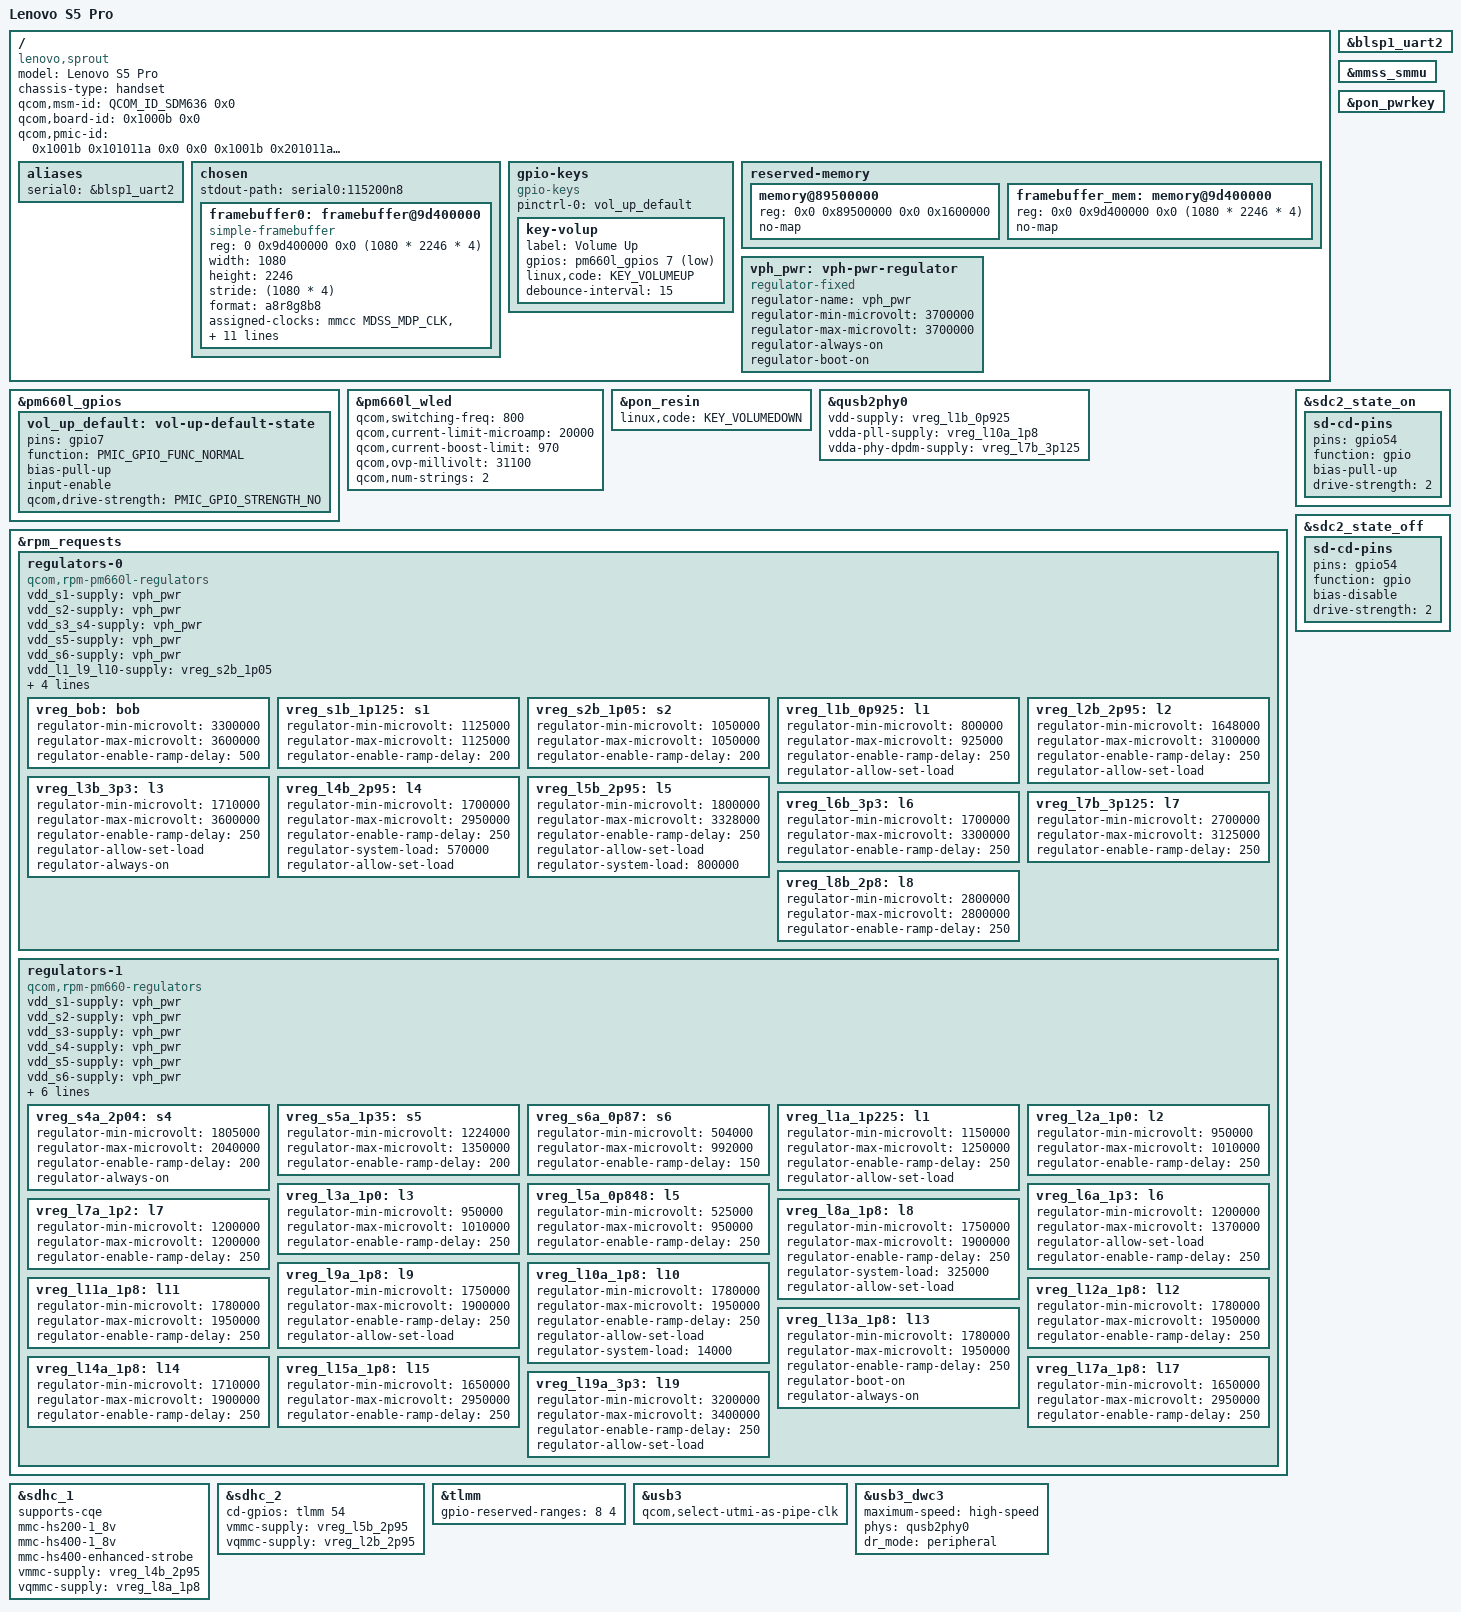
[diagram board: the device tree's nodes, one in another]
// SPDX-License-Identifier: BSD-3-Clause
// SPDX-FileCopyrightText: 2026 Andrey Derkach <gabin278@gmail.com>
/*
 * Lenovo S5 Pro (L58041, "sprout")
 *
 * Based on sdm636-xiaomi-whyred.dts. Board-specific values come from the
 * vendor device tree the stock bootloader selects for this board
 * (msm-id 345, board-id 0x1000b, "SDM 636 PM660 + PM660L QRD").
 */

/dts-v1/;

#include "sdm636.dtsi"
#include "pm660.dtsi"
#include "pm660l.dtsi"
#include <dt-bindings/arm/qcom,ids.h>
#include <dt-bindings/gpio/gpio.h>
#include <dt-bindings/input/input.h>
#include <dt-bindings/input/gpio-keys.h>
#include <dt-bindings/pinctrl/qcom,pmic-gpio.h>

/ {
	model = "Lenovo S5 Pro";
	compatible = "lenovo,sprout", "qcom,sdm636";
	chassis-type = "handset";

	/* Matches the board the stock ABL reports, so it picks this DTB */
	qcom,msm-id = <QCOM_ID_SDM636 0x0>;
	qcom,board-id = <0x1000b 0x0>;
	qcom,pmic-id = <0x1001b 0x101011a 0x0 0x0 0x1001b 0x201011a 0x0 0x0>;

	aliases {
		serial0 = &blsp1_uart2; /* Debug UART */
	};

	chosen {
		#address-cells = <2>;
		#size-cells = <2>;
		ranges;

		stdout-path = "serial0:115200n8";

		framebuffer0: framebuffer@9d400000 {
			compatible = "simple-framebuffer";
			reg = <0 0x9d400000 0x0 (1080 * 2246 * 4)>;
			width = <1080>;
			height = <2246>;
			stride = <(1080 * 4)>;
			format = "a8r8g8b8";

			/*
			 * Keep the bootloader-enabled display stack alive so that
			 * simplefb keeps working without clk_ignore_unused and
			 * pd_ignore_unused.
			 */
			assigned-clocks = <&mmcc MDSS_MDP_CLK>,
					  <&mmcc MDSS_VSYNC_CLK>;
			assigned-clock-rates = <300000000>,
					       <19200000>;
			clocks = <&mmcc MDSS_AHB_CLK>,
				 <&mmcc MDSS_AXI_CLK>,
				 <&mmcc MDSS_VSYNC_CLK>,
				 <&mmcc MDSS_MDP_CLK>,
				 <&mmcc BYTE0_CLK_SRC>,
				 <&mmcc PCLK0_CLK_SRC>,
				 <&mmcc MDSS_BYTE0_CLK>,
				 <&mmcc MDSS_BYTE0_INTF_CLK>,
				 <&mmcc MNOC_AHB_CLK>,
				 <&mmcc MISC_AHB_CLK>,
				 <&mmcc MDSS_PCLK0_CLK>,
				 <&mmcc MDSS_ESC0_CLK>;

			power-domains = <&rpmpd SDM660_VDDCX>, <&mmcc MDSS_GDSC>;
		};
	};

	gpio-keys {
		compatible = "gpio-keys";

		pinctrl-0 = <&vol_up_default>;
		pinctrl-names = "default";

		key-volup {
			label = "Volume Up";
			gpios = <&pm660l_gpios 7 GPIO_ACTIVE_LOW>;
			linux,code = <KEY_VOLUMEUP>;
			debounce-interval = <15>;
		};
	};

	reserved-memory {
		#address-cells = <2>;
		#size-cells = <2>;
		ranges;

		/*
		 * The stock firmware reserves 0x85800000-0x8aafffff
		 * ("removed_regions"), sdm630.dtsi only up to 0x89500000.
		 * SD card DMA into the rest stalls the SDHCI controller and
		 * locks up the system.
		 */
		memory@89500000 {
			reg = <0x0 0x89500000 0x0 0x1600000>;
			no-map;
		};

		framebuffer_mem: memory@9d400000 {
			reg = <0x0 0x9d400000 0x0 (1080 * 2246 * 4)>;
			no-map;
		};
	};

	vph_pwr: vph-pwr-regulator {
		compatible = "regulator-fixed";
		regulator-name = "vph_pwr";
		regulator-min-microvolt = <3700000>;
		regulator-max-microvolt = <3700000>;

		regulator-always-on;
		regulator-boot-on;
	};
};

&blsp1_uart2 {
	status = "okay";
};

/*
 * The display fetches the framebuffer through this SMMU; without it, its
 * clocks are turned off as unused and the simple-framebuffer stops updating.
 */
&mmss_smmu {
	status = "okay";
};

&pm660l_gpios {
	vol_up_default: vol-up-default-state {
		pins = "gpio7";
		function = PMIC_GPIO_FUNC_NORMAL;
		bias-pull-up;
		input-enable;
		qcom,drive-strength = <PMIC_GPIO_STRENGTH_NO>;
	};
};

&pm660l_wled {
	qcom,switching-freq = <800>;
	qcom,current-limit-microamp = <20000>;
	qcom,current-boost-limit = <970>;
	qcom,ovp-millivolt = <31100>;
	qcom,num-strings = <2>;

	status = "okay";
};

&pon_pwrkey {
	status = "okay";
};

&pon_resin {
	linux,code = <KEY_VOLUMEDOWN>;

	status = "okay";
};

&qusb2phy0 {
	vdd-supply = <&vreg_l1b_0p925>;
	vdda-pll-supply = <&vreg_l10a_1p8>;
	vdda-phy-dpdm-supply = <&vreg_l7b_3p125>;

	status = "okay";
};

&rpm_requests {
	regulators-0 {
		compatible = "qcom,rpm-pm660l-regulators";

		vdd_s1-supply = <&vph_pwr>;
		vdd_s2-supply = <&vph_pwr>;
		vdd_s3_s4-supply = <&vph_pwr>;
		vdd_s5-supply = <&vph_pwr>;
		vdd_s6-supply = <&vph_pwr>;

		vdd_l1_l9_l10-supply = <&vreg_s2b_1p05>;
		vdd_l2-supply = <&vreg_bob>;
		vdd_l3_l5_l7_l8-supply = <&vreg_bob>;
		vdd_l4_l6-supply = <&vreg_bob>;
		vdd_bob-supply = <&vph_pwr>;

		vreg_bob: bob {
			regulator-min-microvolt = <3300000>;
			regulator-max-microvolt = <3600000>;
			regulator-enable-ramp-delay = <500>;
		};

		vreg_s1b_1p125: s1 {
			regulator-min-microvolt = <1125000>;
			regulator-max-microvolt = <1125000>;
			regulator-enable-ramp-delay = <200>;
		};

		vreg_s2b_1p05: s2 {
			regulator-min-microvolt = <1050000>;
			regulator-max-microvolt = <1050000>;
			regulator-enable-ramp-delay = <200>;
		};

		/* LDOs */
		vreg_l1b_0p925: l1 {
			regulator-min-microvolt = <800000>;
			regulator-max-microvolt = <925000>;
			regulator-enable-ramp-delay = <250>;
			regulator-allow-set-load;
		};

		/* SDHCI 3.3V signal doesn't seem to be supported. */
		vreg_l2b_2p95: l2 {
			regulator-min-microvolt = <1648000>;
			regulator-max-microvolt = <3100000>;
			regulator-enable-ramp-delay = <250>;
			regulator-allow-set-load;
		};

		vreg_l3b_3p3: l3 {
			regulator-min-microvolt = <1710000>;
			regulator-max-microvolt = <3600000>;
			regulator-enable-ramp-delay = <250>;
			regulator-allow-set-load;
			regulator-always-on;
		};

		vreg_l4b_2p95: l4 {
			regulator-min-microvolt = <1700000>;
			regulator-max-microvolt = <2950000>;
			regulator-enable-ramp-delay = <250>;

			regulator-system-load = <570000>;
			regulator-allow-set-load;
		};

		/*
		 * Downstream specifies a range of 1721-3600mV,
		 * but the only assigned consumers are SDHCI2 VMMC
		 * and Coresight QPDI that both request pinned 2.95V.
		 * Tighten the range to 1.8-3.328 (closest to 3.3) to
		 * make the mmc driver happy.
		 */
		vreg_l5b_2p95: l5 {
			regulator-min-microvolt = <1800000>;
			regulator-max-microvolt = <3328000>;
			regulator-enable-ramp-delay = <250>;
			regulator-allow-set-load;
			regulator-system-load = <800000>;
		};

		/* DSI 3.3V and fingerprint sensor */
		vreg_l6b_3p3: l6 {
			regulator-min-microvolt = <1700000>;
			regulator-max-microvolt = <3300000>;
			regulator-enable-ramp-delay = <250>;
		};

		vreg_l7b_3p125: l7 {
			regulator-min-microvolt = <2700000>;
			regulator-max-microvolt = <3125000>;
			regulator-enable-ramp-delay = <250>;
		};

		vreg_l8b_2p8: l8 {
			regulator-min-microvolt = <2800000>;
			regulator-max-microvolt = <2800000>;
			regulator-enable-ramp-delay = <250>;
		};
	};

	regulators-1 {
		compatible = "qcom,rpm-pm660-regulators";

		vdd_s1-supply = <&vph_pwr>;
		vdd_s2-supply = <&vph_pwr>;
		vdd_s3-supply = <&vph_pwr>;
		vdd_s4-supply = <&vph_pwr>;
		vdd_s5-supply = <&vph_pwr>;
		vdd_s6-supply = <&vph_pwr>;

		vdd_l1_l6_l7-supply = <&vreg_s5a_1p35>;
		vdd_l2_l3-supply = <&vreg_s2b_1p05>;
		vdd_l5-supply = <&vreg_s2b_1p05>;
		vdd_l8_l9_l10_l11_l12_l13_l14-supply = <&vreg_s4a_2p04>;
		vdd_l15_l16_l17_l18_l19-supply = <&vreg_bob>;

		/*
		 * S1A (FTAPC0), S2A (FTAPC1), S3A (HFAPC1) are managed
		 * by the Core Power Reduction hardened (CPRh) and the
		 * Operating State Manager (OSM) HW automatically.
		 */

		vreg_s4a_2p04: s4 {
			regulator-min-microvolt = <1805000>;
			regulator-max-microvolt = <2040000>;
			regulator-enable-ramp-delay = <200>;
			regulator-always-on;
		};

		vreg_s5a_1p35: s5 {
			regulator-min-microvolt = <1224000>;
			regulator-max-microvolt = <1350000>;
			regulator-enable-ramp-delay = <200>;
		};

		vreg_s6a_0p87: s6 {
			regulator-min-microvolt = <504000>;
			regulator-max-microvolt = <992000>;
			regulator-enable-ramp-delay = <150>;
		};

		/* LDOs */
		vreg_l1a_1p225: l1 {
			regulator-min-microvolt = <1150000>;
			regulator-max-microvolt = <1250000>;
			regulator-enable-ramp-delay = <250>;
			regulator-allow-set-load;
		};

		vreg_l2a_1p0: l2 {
			regulator-min-microvolt = <950000>;
			regulator-max-microvolt = <1010000>;
			regulator-enable-ramp-delay = <250>;
		};

		vreg_l3a_1p0: l3 {
			regulator-min-microvolt = <950000>;
			regulator-max-microvolt = <1010000>;
			regulator-enable-ramp-delay = <250>;
		};

		vreg_l5a_0p848: l5 {
			regulator-min-microvolt = <525000>;
			regulator-max-microvolt = <950000>;
			regulator-enable-ramp-delay = <250>;
		};

		vreg_l6a_1p3: l6 {
			regulator-min-microvolt = <1200000>;
			regulator-max-microvolt = <1370000>;
			regulator-allow-set-load;
			regulator-enable-ramp-delay = <250>;
		};

		vreg_l7a_1p2: l7 {
			regulator-min-microvolt = <1200000>;
			regulator-max-microvolt = <1200000>;
			regulator-enable-ramp-delay = <250>;
		};

		vreg_l8a_1p8: l8 {
			regulator-min-microvolt = <1750000>;
			regulator-max-microvolt = <1900000>;
			regulator-enable-ramp-delay = <250>;
			regulator-system-load = <325000>;
			regulator-allow-set-load;
		};

		vreg_l9a_1p8: l9 {
			regulator-min-microvolt = <1750000>;
			regulator-max-microvolt = <1900000>;
			regulator-enable-ramp-delay = <250>;
			regulator-allow-set-load;
		};

		vreg_l10a_1p8: l10 {
			regulator-min-microvolt = <1780000>;
			regulator-max-microvolt = <1950000>;
			regulator-enable-ramp-delay = <250>;
			regulator-allow-set-load;
			regulator-system-load = <14000>;
		};

		vreg_l11a_1p8: l11 {
			regulator-min-microvolt = <1780000>;
			regulator-max-microvolt = <1950000>;
			regulator-enable-ramp-delay = <250>;
		};

		vreg_l12a_1p8: l12 {
			regulator-min-microvolt = <1780000>;
			regulator-max-microvolt = <1950000>;
			regulator-enable-ramp-delay = <250>;
		};

		vreg_l13a_1p8: l13 {
			regulator-min-microvolt = <1780000>;
			regulator-max-microvolt = <1950000>;
			regulator-enable-ramp-delay = <250>;
			regulator-boot-on;
			regulator-always-on;
		};

		vreg_l14a_1p8: l14 {
			regulator-min-microvolt = <1710000>;
			regulator-max-microvolt = <1900000>;
			regulator-enable-ramp-delay = <250>;
		};

		vreg_l15a_1p8: l15 {
			regulator-min-microvolt = <1650000>;
			regulator-max-microvolt = <2950000>;
			regulator-enable-ramp-delay = <250>;
		};

		vreg_l17a_1p8: l17 {
			regulator-min-microvolt = <1650000>;
			regulator-max-microvolt = <2950000>;
			regulator-enable-ramp-delay = <250>;
		};

		vreg_l19a_3p3: l19 {
			regulator-min-microvolt = <3200000>;
			regulator-max-microvolt = <3400000>;
			regulator-enable-ramp-delay = <250>;
			regulator-allow-set-load;
		};
	};
};

&sdc2_state_on {
	sd-cd-pins {
		pins = "gpio54";
		function = "gpio";
		bias-pull-up;
		drive-strength = <2>;
	};
};

&sdc2_state_off {
	sd-cd-pins {
		pins = "gpio54";
		function = "gpio";
		bias-disable;
		drive-strength = <2>;
	};
};

&sdhc_1 {
	supports-cqe;

	mmc-hs200-1_8v;
	mmc-hs400-1_8v;
	mmc-hs400-enhanced-strobe;

	vmmc-supply = <&vreg_l4b_2p95>;
	vqmmc-supply = <&vreg_l8a_1p8>;

	status = "okay";
};

&sdhc_2 {
	cd-gpios = <&tlmm 54 GPIO_ACTIVE_HIGH>;
	vmmc-supply = <&vreg_l5b_2p95>;
	vqmmc-supply = <&vreg_l2b_2p95>;

	status = "okay";
};

&tlmm {
	gpio-reserved-ranges = <8 4>;
};

&usb3 {
	qcom,select-utmi-as-pipe-clk;

	status = "okay";
};

&usb3_dwc3 {
	maximum-speed = "high-speed";
	phys = <&qusb2phy0>;
	phy-names = "usb2-phy";
	dr_mode = "peripheral";
};
